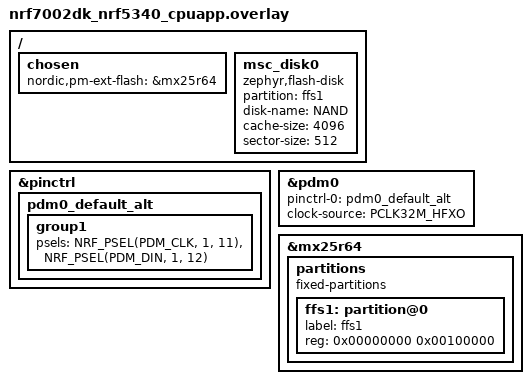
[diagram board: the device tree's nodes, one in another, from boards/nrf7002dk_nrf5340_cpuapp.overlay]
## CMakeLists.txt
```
# SPDX-License-Identifier: Apache-2.0

cmake_minimum_required(VERSION 3.20.0)

find_package(Zephyr REQUIRED HINTS $ENV{ZEPHYR_BASE})
project(reminderGenerativeAI)

target_sources(app PRIVATE 
    src/main.c 
    src/button.c 
    src/reminder.c 
    src/recorder.c 
    src/persistence/persistence.c
)


target_sources_ifdef(CONFIG_WIFI
         app PRIVATE
         src/net/wifi/wifi.c
         src/ai/socket_common.c
         src/ai/whisper.c
         src/ai/completions.c
         )

set(gen_dir ${ZEPHYR_BINARY_DIR}/include/generated/)

generate_inc_file_for_target(
    app
    src/ai/Baltimore\ CyberTrust\ Root.cer
    ${gen_dir}/https-cert.der.inc
    )
```

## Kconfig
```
# Config options for logger sample app

# Copyright (c) 2018 Nordic Semiconductor ASA
# SPDX-License-Identifier: Apache-2.0

mainmenu "Home control with open.ai"

menu "Application configuration"

rsource "Kconfig.net"

config OPENAI_API_KEY
	string "API Key for Open.ai"
	help
	  Specify the API Key for Open.ai


module = MAIN
module-str = Home control by voice
source "subsys/logging/Kconfig.template.log_config"

endmenu

source "Kconfig.zephyr"
```

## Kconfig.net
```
#
# Copyright (c) 2022 Nordic Semiconductor
#
# SPDX-License-Identifier: LicenseRef-Nordic-5-Clause
#

if WIFI

config STA_SAMPLE_SSID
	string "SSID"
	help
	  Specify the SSID to connect

choice  STA_KEY_MGMT_SELECT
	prompt "Security Option"
	default STA_KEY_MGMT_WPA3

config STA_KEY_MGMT_NONE
	bool "Open Security"
	help
	  Enable for Open Security

config STA_KEY_MGMT_WPA2
	bool "WPA2 Security"
	help
	  Enable for WPA2 Security

config STA_KEY_MGMT_WPA2_256
	bool "WPA2 SHA 256 Security"
	help
	  Enable for WPA2-PSK-256 Security

config STA_KEY_MGMT_WPA3
	bool "WPA3 Security"
	help
	  Enable for WPA3 Security
endchoice

config STA_SAMPLE_PASSWORD
	string "Passphrase (WPA2) or password (WPA3)"
	help
	  Specify the Password to connect

endif
```

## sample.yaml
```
sample:
  description: open.ai
  name: open.ai
tests:
  open_ai.debug:
    build_only: true
    integration_platforms:
      - nrf7002dk_nrf5340_cpuapp
    platform_allow: nrf7002dk_nrf5340_cpuapp
```

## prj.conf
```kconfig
#################
# Debugging
#################
# Debug information
CONFIG_DEBUG=y
CONFIG_DEBUG_INFO=y
CONFIG_EXCEPTION_STACK_TRACE=y
CONFIG_THREAD_NAME=y
CONFIG_MPU_STACK_GUARD=y
CONFIG_RESET_ON_FATAL_ERROR=n

CONFIG_INIT_STACKS=y
CONFIG_STACK_SENTINEL=y
#CONFIG_DEBUG_COREDUMP=y
#CONFIG_DEBUG_COREDUMP_BACKEND_LOGGING=y
#CONFIG_STACK_USAGE=y
#CONFIG_THREAD_ANALYZER=y
#CONFIG_THREAD_ANALYZER_USE_LOG=y
#CONFIG_THREAD_ANALYZER_AUTO=y
#CONFIG_SYS_HEAP_RUNTIME_STATS=y



############
# Memory settings
############
CONFIG_SYSTEM_WORKQUEUE_STACK_SIZE=8192
CONFIG_NET_TX_STACK_SIZE=4096

# https://developer.nordicsemi.com/nRF_Connect_SDK/doc/latest/nrf/device_guides/working_with_nrf/nrf70/developing/constrained.html
# Buffers for network and nRF7002
CONFIG_NET_PKT_RX_COUNT=8
CONFIG_NET_PKT_TX_COUNT=8
CONFIG_NET_BUF_RX_COUNT=16
CONFIG_NET_BUF_TX_COUNT=32

CONFIG_NET_BUF_DATA_SIZE=128
CONFIG_HEAP_MEM_POOL_SIZE=51200
CONFIG_HW_STACK_PROTECTION=y
CONFIG_NET_TC_TX_COUNT=1

CONFIG_NRF700X_RX_NUM_BUFS=12
CONFIG_NRF700X_MAX_TX_AGGREGATION=12
CONFIG_NRF700X_MAX_TX_TOKENS=10
CONFIG_NRF700X_TX_MAX_DATA_SIZE=1600
CONFIG_NRF700X_RX_MAX_DATA_SIZE=800
CONFIG_NET_SOCKETPAIR_BUFFER_SIZE=4096



##########
# logging
##########
CONFIG_LOG=y
CONFIG_LOG_MODE_MINIMAL=n
CONFIG_LOG_MODE_DEFERRED=y
CONFIG_LOG_MODE_IMMEDIATE=n
CONFIG_LOG_BUFFER_SIZE=8192
CONFIG_LOG_BACKEND_SHOW_COLOR=n
CONFIG_LOG_BACKEND_UART=y
CONFIG_SHELL_LOG_BACKEND=n

CONFIG_MAIN_LOG_LEVEL_DBG=y
CONFIG_DATE_TIME_LOG_LEVEL_DBG=y
CONFIG_USB_DRIVER_LOG_LEVEL_ERR=y
CONFIG_USB_DEVICE_LOG_LEVEL_ERR=y
CONFIG_USB_MASS_STORAGE_LOG_LEVEL_ERR=y
CONFIG_USB_CDC_ACM_LOG_LEVEL_OFF=y
CONFIG_NET_HTTP_LOG_LEVEL_DBG=y



############
# USB
############
CONFIG_USB_DEVICE_STACK=y
CONFIG_USB_DEVICE_PRODUCT="Feather Chat"
CONFIG_USB_CDC_ACM=n
CONFIG_UART_LINE_CTRL=y
CONFIG_USB_REQUEST_BUFFER_SIZE=2048

CONFIG_USB_DEVICE_VID=0x1234
CONFIG_USB_DEVICE_PID=0x5678

CONFIG_USB_DEVICE_MANUFACTURER="J"
CONFIG_USB_DEVICE_SN="MLB_000000000000"

CONFIG_USB_DEVICE_INITIALIZE_AT_BOOT=n

CONFIG_USB_COMPOSITE_DEVICE=n
CONFIG_USB_MAX_NUM_TRANSFERS=8



############
# Wifi
############
CONFIG_WIFI=y
CONFIG_WIFI_NRF700X=y

# WPA supplicant
CONFIG_WPA_SUPP=y




############
# Networking
############
CONFIG_NETWORKING=y
CONFIG_NET_SOCKETS=y
CONFIG_NET_LOG=y
CONFIG_NET_IPV4=y
CONFIG_NET_UDP=y
CONFIG_NET_TCP=y
CONFIG_NET_DHCPV4=y

CONFIG_NET_L2_ETHERNET=y
CONFIG_NET_CONFIG_SETTINGS=y
CONFIG_NET_SOCKETS_POLL_MAX=6
CONFIG_NET_IF_UNICAST_IPV4_ADDR_COUNT=1
CONFIG_NET_MAX_CONTEXTS=5
CONFIG_NET_CONTEXT_SYNC_RECV=y

CONFIG_NET_MGMT=y
CONFIG_NET_MGMT_EVENT=y
CONFIG_NET_MGMT_EVENT_QUEUE_TIMEOUT=5000
CONFIG_NET_MGMT_EVENT_QUEUE_SIZE=150

CONFIG_NET_SOCKETS_SOCKOPT_TLS=y
CONFIG_NET_SOCKETS_TLS_MAX_CONTEXTS=2
CONFIG_NET_SOCKETS_TLS_SET_MAX_FRAGMENT_LENGTH=y

CONFIG_DNS_RESOLVER=y
CONFIG_DNS_RESOLVER_MAX_SERVERS=1
CONFIG_DNS_SERVER_IP_ADDRESSES=y
CONFIG_DNS_NUM_CONCUR_QUERIES=1
CONFIG_DNS_SERVER1="8.8.8.8"



############
# MbedTLS and security
############
CONFIG_MBEDTLS=y
CONFIG_MBEDTLS_TLS_LIBRARY=y
CONFIG_MBEDTLS_X509_LIBRARY=y
CONFIG_MBEDTLS_PKCS1_V15=y
CONFIG_MBEDTLS_RSA_C=y
CONFIG_MBEDTLS_SSL_SERVER_NAME_INDICATION=y

# These sizes are required to establish ssl connection with open.ai
CONFIG_MBEDTLS_ENABLE_HEAP=y
CONFIG_MBEDTLS_SSL_IN_CONTENT_LEN=4096
CONFIG_MBEDTLS_SSL_OUT_CONTENT_LEN=4096
CONFIG_MBEDTLS_HEAP_SIZE=32768

CONFIG_NRF_SECURITY_ADVANCED=y
CONFIG_NORDIC_SECURITY_BACKEND=y
CONFIG_PSA_WANT_ALG_SHA_1=y
CONFIG_PSA_WANT_ALG_RSA_PKCS1V15_CRYPT=y
CONFIG_PSA_WANT_ALG_RSA_PKCS1V15_SIGN=y

CONFIG_PSA_CRYPTO_DRIVER_CC3XX=n



############
# Other
############
CONFIG_ENTROPY_GENERATOR=y
CONFIG_POSIX_CLOCK=y
CONFIG_POLL=y
CONFIG_PM=y



############
# App
############
CONFIG_HTTP_CLIENT=y

CONFIG_NRFX_PDM=y

CONFIG_DK_LIBRARY=y

CONFIG_CJSON_LIB=y

CONFIG_NEWLIB_LIBC=y
CONFIG_NEWLIB_LIBC_FLOAT_PRINTF=y

CONFIG_DATE_TIME=y
CONFIG_DATE_TIME_NTP=y

CONFIG_AUDIO=y
CONFIG_AUDIO_DMIC=y



############
# Flash / Disk / USB Mass Storage
############
CONFIG_DISK_ACCESS=y
CONFIG_FILE_SYSTEM=y
CONFIG_FAT_FILESYSTEM_ELM=y
CONFIG_FS_FATFS_LFN=y

CONFIG_POSIX_MAX_FDS=16

# Need this when storage is on flash
CONFIG_MPU_ALLOW_FLASH_WRITE=y

CONFIG_FLASH=y
CONFIG_FLASH_MAP=y
CONFIG_FLASH_PAGE_LAYOUT=y
# nRF7002dk does not connect to QSPI
CONFIG_SPI_NOR_FLASH_LAYOUT_PAGE_SIZE=4096

CONFIG_USB_MASS_STORAGE=y
CONFIG_MASS_STORAGE_STACK_SIZE=1024

CONFIG_DISK_DRIVER_FLASH=y
# defaults if CONFIG_DISK_DRIVER_FLASH=y
CONFIG_MASS_STORAGE_DISK_NAME="NAND"
CONFIG_FLASHDISK_VERIFY_PAGE_LAYOUT=y
```

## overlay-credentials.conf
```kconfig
CONFIG_OPENAI_API_KEY="__REPLACE_ME__"

# Security
CONFIG_STA_KEY_MGMT_WPA3=y
CONFIG_STA_SAMPLE_SSID="__REPLACE_ME__"
CONFIG_STA_SAMPLE_PASSWORD="__REPLACE_ME__"
```

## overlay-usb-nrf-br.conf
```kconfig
############
# USB
############
CONFIG_USB_DEVICE_STACK=y
CONFIG_USB_DEVICE_PRODUCT="Feather Chat"
CONFIG_USB_CDC_ACM=y
CONFIG_UART_LINE_CTRL=y
CONFIG_USB_REQUEST_BUFFER_SIZE=2048

CONFIG_USB_DEVICE_VID=0x1234
CONFIG_USB_DEVICE_PID=0x5678

CONFIG_USB_DEVICE_MANUFACTURER="J"
CONFIG_USB_DEVICE_SN="MLB_000000000000"

CONFIG_USB_DEVICE_INITIALIZE_AT_BOOT=n

CONFIG_USB_COMPOSITE_DEVICE=n
CONFIG_USB_MAX_NUM_TRANSFERS=8

#CONFIG_ISR_STACK_SIZE=4096

CONFIG_USB_CDC_ACM_LOG_LEVEL_OFF=y

CONFIG_USB_MASS_STORAGE=y
CONFIG_MASS_STORAGE_STACK_SIZE=1024
CONFIG_USB_DRIVER_LOG_LEVEL_ERR=y
CONFIG_USB_DEVICE_LOG_LEVEL_ERR=y
CONFIG_USB_MASS_STORAGE_LOG_LEVEL_ERR=y

CONFIG_DISK_DRIVER_FLASH=y
# defaults if CONFIG_DISK_DRIVER_FLASH=y
CONFIG_MASS_STORAGE_DISK_NAME="NAND"
CONFIG_FLASHDISK_VERIFY_PAGE_LAYOUT=y
```

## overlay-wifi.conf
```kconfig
############
# Wifi
############
CONFIG_WIFI=y
CONFIG_WIFI_NRF700X=y

# WPA supplicant
CONFIG_WPA_SUPP=y

# Security
CONFIG_STA_KEY_MGMT_WPA3=y
CONFIG_STA_SAMPLE_SSID="__REPLACE_ME__"
CONFIG_STA_SAMPLE_PASSWORD="__REPLACE_ME__"



############
# Networking
############
CONFIG_NETWORKING=y
CONFIG_NET_SOCKETS=y
CONFIG_NET_LOG=y
CONFIG_NET_IPV4=y
CONFIG_NET_UDP=y
CONFIG_NET_TCP=y
CONFIG_NET_DHCPV4=y

CONFIG_NET_L2_ETHERNET=y
CONFIG_NET_CONFIG_SETTINGS=y
CONFIG_NET_SOCKETS_POLL_MAX=6
CONFIG_NET_IF_UNICAST_IPV4_ADDR_COUNT=1
CONFIG_NET_MAX_CONTEXTS=5
CONFIG_NET_CONTEXT_SYNC_RECV=y

CONFIG_NET_MGMT=y
CONFIG_NET_MGMT_EVENT=y
CONFIG_NET_MGMT_EVENT_QUEUE_TIMEOUT=5000
CONFIG_NET_MGMT_EVENT_QUEUE_SIZE=150

CONFIG_NET_SOCKETS_SOCKOPT_TLS=y
CONFIG_NET_SOCKETS_TLS_MAX_CONTEXTS=2
CONFIG_NET_SOCKETS_TLS_SET_MAX_FRAGMENT_LENGTH=y

CONFIG_DNS_RESOLVER=y
CONFIG_DNS_RESOLVER_MAX_SERVERS=1
CONFIG_DNS_SERVER_IP_ADDRESSES=y
CONFIG_DNS_NUM_CONCUR_QUERIES=1
CONFIG_DNS_SERVER1="8.8.8.8"



############
# MbedTLS and security
############
CONFIG_MBEDTLS=y
CONFIG_MBEDTLS_TLS_LIBRARY=y
CONFIG_MBEDTLS_X509_LIBRARY=y
CONFIG_MBEDTLS_PKCS1_V15=y
CONFIG_MBEDTLS_RSA_C=y
CONFIG_MBEDTLS_SSL_SERVER_NAME_INDICATION=y

# These sizes are required to establish ssl connection with open.ai
CONFIG_MBEDTLS_ENABLE_HEAP=y
CONFIG_MBEDTLS_SSL_IN_CONTENT_LEN=4096
CONFIG_MBEDTLS_SSL_OUT_CONTENT_LEN=4096
CONFIG_MBEDTLS_HEAP_SIZE=32768

CONFIG_NRF_SECURITY_ADVANCED=y
CONFIG_NORDIC_SECURITY_BACKEND=y
CONFIG_PSA_WANT_ALG_SHA_1=y
CONFIG_PSA_WANT_ALG_RSA_PKCS1V15_CRYPT=y
CONFIG_PSA_WANT_ALG_RSA_PKCS1V15_SIGN=y

CONFIG_PSA_CRYPTO_DRIVER_CC3XX=n



############
# Memory
############
CONFIG_SYSTEM_WORKQUEUE_STACK_SIZE=8192

# https://developer.nordicsemi.com/nRF_Connect_SDK/doc/latest/nrf/device_guides/working_with_nrf/nrf70/developing/constrained.html
# Buffers for network and nRF7002
CONFIG_NET_PKT_RX_COUNT=8
CONFIG_NET_PKT_TX_COUNT=8
CONFIG_NET_BUF_RX_COUNT=16
CONFIG_NET_BUF_TX_COUNT=32

CONFIG_NET_BUF_DATA_SIZE=128
CONFIG_HEAP_MEM_POOL_SIZE=51200
CONFIG_HW_STACK_PROTECTION=y
CONFIG_NET_TC_TX_COUNT=1

CONFIG_NRF700X_RX_NUM_BUFS=12
CONFIG_NRF700X_MAX_TX_AGGREGATION=12
CONFIG_NRF700X_MAX_TX_TOKENS=10
CONFIG_NRF700X_TX_MAX_DATA_SIZE=1600
CONFIG_NRF700X_RX_MAX_DATA_SIZE=800
CONFIG_NET_SOCKETPAIR_BUFFER_SIZE=4096



############
# Debugging
############
CONFIG_INIT_STACKS=y
CONFIG_STACK_SENTINEL=y
CONFIG_DEBUG_COREDUMP=y
CONFIG_DEBUG_COREDUMP_BACKEND_LOGGING=y
#CONFIG_STACK_USAGE=y
#CONFIG_THREAD_ANALYZER=y
#CONFIG_THREAD_ANALYZER_USE_LOG=y
#CONFIG_THREAD_ANALYZER_AUTO=y
#CONFIG_SYS_HEAP_RUNTIME_STATS=y



############
# Other
############
CONFIG_ENTROPY_GENERATOR=y
CONFIG_POSIX_CLOCK=y
CONFIG_PM=y



############
# App
############
CONFIG_HTTP_CLIENT=y
CONFIG_NET_HTTP_LOG_LEVEL_DBG=y
```

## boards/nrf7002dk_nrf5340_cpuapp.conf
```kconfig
# Need this when storage is on flash
CONFIG_MPU_ALLOW_FLASH_WRITE=y

CONFIG_SPI_NOR_FLASH_LAYOUT_PAGE_SIZE=4096

CONFIG_FLASH=y
CONFIG_FLASH_MAP=y
CONFIG_FLASH_PAGE_LAYOUT=y
```

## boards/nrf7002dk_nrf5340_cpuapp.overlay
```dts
/ {
	chosen {
		nordic,pm-ext-flash = &mx25r64;
	};

	msc_disk0 {
		compatible = "zephyr,flash-disk";
		partition = <&ffs1>;
		// disk-name must be one of "RAM","NAND","CF","SD","SD2","USB","USB2","USB3"
		disk-name = "NAND";
		cache-size = <4096>;
		// when changing sector-size, adapt CONFIG_FS_FATFS_MAX_SS or crash
		sector-size = <512>;
	};
};

&pinctrl {
	pdm0_default_alt: pdm0_default_alt {
		group1 {
			psels = <NRF_PSEL(PDM_CLK, 1, 11)>,
				<NRF_PSEL(PDM_DIN, 1, 12)>;
		};
	};
};

dmic_dev: &pdm0 {
	status = "okay";
	pinctrl-0 = <&pdm0_default_alt>;
	pinctrl-names = "default";
	clock-source = "PCLK32M_HFXO";
};

&mx25r64 {
	partitions {
		compatible = "fixed-partitions";
		#address-cells = <1>;
		#size-cells = <1>;

		ffs1: partition@0 {
			label = "ffs1";			
			reg = <0x00000000 0x00100000>;
		};
	};
};
```

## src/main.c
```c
#include <zephyr/kernel.h>
#include <zephyr/logging/log.h>
#include <zephyr/usb/usb_device.h>

#include "ai/completions.h"
#include "ai/definitions.h"
#include "ai/whisper.h"
#include "button.h"
#include "cJSON.h"
#include "persistence/persistence.h"
#include "recorder.h"
#include "reminder.h"
LOG_MODULE_REGISTER(app, CONFIG_MAIN_LOG_LEVEL);

// Magic global variable that holds the results of the requests to open.ai
extern char response_buf[MAX_EXPECTED_RESPONSE_BODY];

static void parse_json(const char *data) {
  LOG_INF("Parsing completion result %s", data);

  cJSON *jsonRoot = cJSON_Parse(data);
  if (!cJSON_IsObject(jsonRoot)) {
    const char *error_ptr = cJSON_GetErrorPtr();
    if (error_ptr != NULL) {
      LOG_ERR("Error before: %s", error_ptr);
    }
    goto end;
  }

  cJSON *jsonRequest = cJSON_GetObjectItemCaseSensitive(jsonRoot, "request");
  if (!cJSON_IsString(jsonRequest)) {
    LOG_ERR("No request available");
    goto end;
  }
  const char *requestString = jsonRequest->valuestring;

  cJSON *jsonParameter = cJSON_GetObjectItemCaseSensitive(jsonRoot, "parameter");
  if (!cJSON_IsObject(jsonParameter)) {
    LOG_ERR("No parameter available");
    goto end;
  }

  cJSON *jsonName = cJSON_GetObjectItemCaseSensitive(jsonParameter, "name");
  if (!cJSON_IsString(jsonName)) {
    LOG_ERR("No name available");
    goto end;
  }
  const char *nameString = jsonName->valuestring;

  if (strcmp(requestString, "delete") == 0) {
    deleteReminder(nameString);
  } else if (strcmp(requestString, "add") == 0) {
    cJSON *jsonDue = cJSON_GetObjectItemCaseSensitive(jsonParameter, "due");
    if (!cJSON_IsString(jsonDue)) {
      LOG_ERR("No due available");
      goto end;
    }
    const char *dueString = jsonDue->valuestring;
    addReminder(nameString, dueString);
  }

end:
  cJSON_Delete(jsonRoot);
}

static void onRecordingFinished(struct k_work *work) {
  struct work_with_data *work_data = CONTAINER_OF(work, struct work_with_data, work);
  request_transcription(work_data->path);
  response_buf[strcspn(response_buf, "\n")] = 0;
  request_chat_completion(response_buf);
  parse_json(response_buf);
  LOG_INF("NEXT ALARM UNTIL %llu",checkdue());
}

int main(void) {
  int ret;

#if defined(CONFIG_USB_DEVICE_STACK)
  usb_enable(NULL);
#endif

  LOG_INF("Start of ChatGPT");

  k_work_init_delayable(&onRecordingFinishedWork.work, onRecordingFinished);

  fs_init(false);
  button_init();

  while (true) {
    LOG_INF("WAIT FOR BUTTON");
    k_poll(recordButtonEvents, ARRAY_SIZE(recordButtonEvents), K_FOREVER);
    if (recordButtonEvents[0].signal->result == BUTTON_PUSHED) {
      k_poll_signal_reset(&recordButtonSignal);
      LOG_INF("START RECORDING");

      ret = do_pdm_transfer();
      if (ret < 0) {
        return 0;
      }

      LOG_INF("STOP RECORDING");
    }
  }

  LOG_INF("Exiting");
  return 0;
}
```

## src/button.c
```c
#include "button.h"

#include <dk_buttons_and_leds.h>
#include <zephyr/kernel.h>
#include <zephyr/logging/log.h>
LOG_MODULE_REGISTER(button, CONFIG_MAIN_LOG_LEVEL);

#define RECORD_BUTTON_MASK DK_BTN1_MSK

struct k_poll_signal recordButtonSignal;
struct k_poll_event recordButtonEvents[1];

void ButtonEventHandler(uint32_t buttonState, uint32_t hasChanged) {
  if (RECORD_BUTTON_MASK & hasChanged) {
    if (RECORD_BUTTON_MASK & buttonState) {
      // pushed
      k_poll_signal_raise(&recordButtonSignal, BUTTON_PUSHED);
    } else {
      // released
      k_poll_signal_raise(&recordButtonSignal, BUTTON_RELEASED);
    }
  }
}

int button_init() {
  /* Initialize buttons */
  int ret = dk_buttons_init(ButtonEventHandler);
  if (ret) {
    LOG_ERR("dk_buttons_init() failed");
    return ret;
  }

  k_poll_signal_init(&recordButtonSignal);
  k_poll_event_init(recordButtonEvents, K_POLL_TYPE_SIGNAL, K_POLL_MODE_NOTIFY_ONLY,
                    &recordButtonSignal);

  return 0;
}
```

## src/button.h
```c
#pragma once

#include <zephyr/kernel.h>

enum buttonEvent { BUTTON_PUSHED, BUTTON_RELEASED };

extern struct k_poll_signal recordButtonSignal;
extern struct k_poll_event recordButtonEvents[1];

int button_init();
```

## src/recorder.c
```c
#include "recorder.h"

#include <nrfx_pdm.h>
#include <stdio.h>
#include <zephyr/kernel.h>
#include <zephyr/logging/log.h>

#include "button.h"
#include "persistence/persistence.h"

LOG_MODULE_REGISTER(audio_recorder, CONFIG_MAIN_LOG_LEVEL);

struct work_with_data onRecordingFinishedWork;

/* Milliseconds to wait for a block to be read. */
#define READ_TIMEOUT 2000

/* Audio sampling config */
#define AUDIO_CHANNEL_NUM           1
#define AUDIO_SAMPLING_FREQUENCY    8000
#define AUDIO_SAMPLES_PER_MS        (AUDIO_SAMPLING_FREQUENCY / 1000)
#define AUDIO_DSP_SAMPLE_LENGTH_MS  1500
#define AUDIO_DSP_SAMPLE_RESOLUTION (sizeof(short))
#define AUDIO_DSP_SAMPLE_BUFFER_SIZE \
  (AUDIO_SAMPLES_PER_MS * AUDIO_DSP_SAMPLE_LENGTH_MS * AUDIO_DSP_SAMPLE_RESOLUTION)
#define PDM_CLK_PIN                 43  // 32+11 = p1.11
#define PDM_DIN_PIN                 44  // 32+12 = p1.12
#define BUFFER_COUNT                4

K_MEM_SLAB_DEFINE_STATIC(mem_slab, AUDIO_DSP_SAMPLE_BUFFER_SIZE, BUFFER_COUNT, sizeof(void *));
K_MSGQ_DEFINE(rx_queue, sizeof(void *), 4, sizeof(void *));


// http://soundfile.sapp.org/doc/WaveFormat/
struct wav_hdr {
  uint8_t RIFF[4];
  uint32_t ChunkSize;
  uint8_t WAVE[4];
  uint8_t fmt[4];
  uint32_t Subchunk1Size;
  uint16_t AudioFormat;
  uint16_t NumOfChan;
  uint32_t SamplesPerSec;
  uint32_t bytesPerSec;
  uint16_t blockAlign;
  uint16_t bitsPerSample;
  uint8_t Subchunk2ID[4];
  uint32_t Subchunk2Size;
};

const struct wav_hdr WAV_DEFAULTS = {{'R', 'I', 'F', 'F'},
                                     0,
                                     {'W', 'A', 'V', 'E'},
                                     {'f', 'm', 't', ' '},
                                     16,
                                     1,
                                     AUDIO_CHANNEL_NUM,
                                     AUDIO_SAMPLING_FREQUENCY,
                                     AUDIO_SAMPLING_FREQUENCY * 2,
                                     2,
                                     8 * sizeof(short),
                                     {'d', 'a', 't', 'a'},
                                     0};


static void samples_callback(nrfx_pdm_evt_t const *p_evt) {
  if (p_evt->error != 0) {
    LOG_ERR("ERR: PDM handler error ocured");
    LOG_ERR("ERR: samples_callback error: %d, %d", p_evt->error, p_evt->buffer_requested);
    return;
  }

  if (p_evt->buffer_requested) {
    void *buffer;
    int err;

    err = k_mem_slab_alloc(&mem_slab, &buffer, K_NO_WAIT);

    if (err < 0) {
      LOG_ERR("Failed to allocate buffer: %d", err);
    } else {
      // size is 16-bit words
      err = nrfx_pdm_buffer_set(buffer, AUDIO_DSP_SAMPLE_BUFFER_SIZE / 2);
      if (err != NRFX_SUCCESS) {
        LOG_ERR("Failed to set buffer: 0x%08x", err);
      }
    }
  }

  if (p_evt->buffer_released != NULL) {
    k_msgq_put(&rx_queue, &p_evt->buffer_released, K_NO_WAIT);
  }
  
  uint32_t used = k_mem_slab_num_used_get(&mem_slab);
  LOG_INF("Allocated %d of %d bytes", used * AUDIO_DSP_SAMPLE_BUFFER_SIZE,
          BUFFER_COUNT * AUDIO_DSP_SAMPLE_BUFFER_SIZE);
}

static bool setup_nrf_pdm(nrfx_pdm_event_handler_t event_handler) {
  nrfx_err_t err;

  // PDM driver configuration
  nrfx_pdm_config_t config_pdm = NRFX_PDM_DEFAULT_CONFIG(PDM_CLK_PIN, PDM_DIN_PIN);
  if (AUDIO_SAMPLING_FREQUENCY == 8000) {
    // taken from firmware-nordic-thingy53/drivers/vm3011/vm3011.c l.346
    config_pdm.clock_freq = 0x04104000UL;
    config_pdm.ratio = NRF_PDM_RATIO_64X;
  } else if (AUDIO_SAMPLING_FREQUENCY == 16000) {
    config_pdm.clock_freq = NRF_PDM_FREQ_1280K;
    config_pdm.ratio = NRF_PDM_RATIO_80X;
  }
  config_pdm.edge = NRF_PDM_EDGE_LEFTRISING;
  config_pdm.gain_l = NRF_PDM_GAIN_MAXIMUM;
  config_pdm.gain_r = NRF_PDM_GAIN_MAXIMUM;
  // defaults below
  config_pdm.mode = NRF_PDM_MODE_MONO;
  config_pdm.mclksrc = PDM_MCLKCONFIG_SRC_PCLK32M;
  config_pdm.interrupt_priority = NRFX_PDM_DEFAULT_CONFIG_IRQ_PRIORITY;

  IRQ_DIRECT_CONNECT(PDM0_IRQn, IRQ_PRIO_LOWEST, nrfx_pdm_irq_handler, 0);

  err = nrfx_pdm_init(&config_pdm, event_handler);
  if (err != NRFX_SUCCESS) {
    LOG_ERR("Failed to init PDM");
    return false;
  } else {
    if (!irq_is_enabled(PDM0_IRQn)) {
      irq_enable(PDM0_IRQn);
    }
    LOG_DBG("PDM init ok");
    return true;
  }
}

int do_pdm_transfer() {
  int ret;

  nrfx_pdm_uninit();
  if (!setup_nrf_pdm(samples_callback)) {
    LOG_ERR("Error microphone init");
    return -1;
  }

  ret = nrfx_pdm_start();
  if (ret != NRFX_SUCCESS) {
    LOG_ERR("Error microphone start");
    return ret;
  }

  // path of temp file
  uint32_t uptime = (uint32_t)(k_uptime_get() / 1000);
  char path[32];
  snprintf(path, 32, "rec-%d", uptime);

  // skip the first frame (1.5s!) since there is a click sound in the first 500ms
  uint8_t skip = 1;
  // total size to update the wave hearder
  uint32_t total_size = 0;
  struct wav_hdr header = WAV_DEFAULTS;
  fs_appendData(path, &header, sizeof(header));

  for (int i = 0; true; ++i) {
    void *buffer;

    ret = k_msgq_get(&rx_queue, &buffer, SYS_TIMEOUT_MS(READ_TIMEOUT));

    if (ret != 0) {
      LOG_ERR("No audio data to be read. Finished");

      ret = nrfx_pdm_stop();
      if (ret != NRFX_SUCCESS) {
        LOG_ERR("ERR: PDM Could not stop PDM sampling, error = %d", ret);
      }      

      break;
    } else {
      LOG_DBG("Released buffer %p", buffer);
    }

    if (skip > 0) {
      skip--;
    } else {
      fs_appendData(path, buffer, AUDIO_DSP_SAMPLE_BUFFER_SIZE);
      total_size += AUDIO_DSP_SAMPLE_BUFFER_SIZE;
    }

    k_mem_slab_free(&mem_slab, buffer);

    // Check if the recording shall be stopped
    int rc = k_poll(recordButtonEvents, ARRAY_SIZE(recordButtonEvents), K_NO_WAIT);
    if (rc == 0 && recordButtonEvents[0].signal->result == BUTTON_RELEASED) {
      k_poll_signal_reset(&recordButtonSignal);

      ret = nrfx_pdm_stop();
      if (ret != NRFX_SUCCESS) {
        LOG_ERR("ERR: PDM Could not stop PDM sampling, error = %d", ret);
      }
    }
  }

  // update the wave header
  header.Subchunk2Size = total_size;
  header.ChunkSize = header.Subchunk2Size + 36;
  fs_overwriteData(path, &header, sizeof(header), 0);

  // schedule the transcription
  memcpy(onRecordingFinishedWork.path, path, sizeof(path));
  k_work_reschedule(&onRecordingFinishedWork.work, K_SECONDS(2));

  return ret;
}
```

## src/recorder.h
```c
#pragma once

#include <zephyr/kernel.h>

// interface between main and recorder
struct work_with_data {
  struct k_work_delayable work;
  char path[32];
};

extern struct work_with_data onRecordingFinishedWork;

int do_pdm_transfer();
```

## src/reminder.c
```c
#include "reminder.h"

#include <date_time.h>
#include <stdio.h>
#include <zephyr/kernel.h>
#include <zephyr/logging/log.h>
LOG_MODULE_REGISTER(reminder, CONFIG_MAIN_LOG_LEVEL);

struct reminder reminders[10];

int64_t parseTime(const char *dueDate) {
  // https://stackoverflow.com/questions/2722606/how-to-parse-a-string-into-a-datetime-struct-in-c
  struct tm *parsedTime;
  int hour, minute, month, day;
  if (sscanf(dueDate, "%d-%d %d:%d", &month, &day, &hour, &minute) != EOF) {
    time_t rawTime = 0;
    parsedTime = localtime(&rawTime);

    // tm_year is years since 1900
    parsedTime->tm_year = 2023 - 1900;
    // tm_months is months since january
    parsedTime->tm_mon = month - 1;
    parsedTime->tm_mday = day;
    parsedTime->tm_hour = hour;
    parsedTime->tm_min = minute;
    return mktime(parsedTime);
  }
  return -1;
}

void addReminder(const char *name, const char *dueDate) {
  for (size_t i = 0; i < ARRAY_SIZE(reminders); i++) {
    if (reminders[i].name[0] == 0) {
      strncpy(reminders[i].name, name, 50);
      reminders[i].dueDate = parseTime(dueDate);
      LOG_INF("Added reminder %s at %llu", reminders[i].name, reminders[i].dueDate);
      break;
    }
  }
}

void deleteReminder(const char *name) {
  for (size_t i = 0; i < ARRAY_SIZE(reminders); i++) {
    if (strcmp(reminders[i].name, name) == 0) {
      LOG_INF("Delete reminder %s at %llu", reminders[i].name, reminders[i].dueDate);
      reminders[i].name[0] = 0;
      break;
    }
  }
}

int64_t checkdue() {
  int64_t timeUntilNextDue = LONG_MAX;
  int64_t now = -1;
  int rc = date_time_now(&now);
  if (rc >= 0) {
    now = now / 1000 + TIME_ZONE_SHIFT;

    for (size_t i = 0; i < ARRAY_SIZE(reminders); i++) {
      if (reminders[i].name[0] != 0) {
        int64_t remainingTime = reminders[i].dueDate - now;
        LOG_INF("Check reminder %s at %llu, remaining %llu", reminders[i].name, reminders[i].dueDate,
                remainingTime);
        timeUntilNextDue = MIN(timeUntilNextDue, remainingTime);
      }
    }
  }
  return timeUntilNextDue;
}
```

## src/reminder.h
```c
#pragma once

#include <zephyr/kernel.h>

#define TIME_ZONE_SHIFT (9 * 60 * 60)

struct reminder {
  char name[50];
  int64_t dueDate;
};

void addReminder(const char *name, const char *dueDate);
void deleteReminder(const char *name);
int64_t checkdue();
```

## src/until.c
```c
#include <zephyr/sys/sys_heap.h>

#if defined(CONFIG_SYS_HEAP_RUNTIME_STATS)
extern struct sys_heap _system_heap;
#endif

void print_sys_memory_stats(void) {
#if defined(CONFIG_SYS_HEAP_RUNTIME_STATS)
  int err;
  struct sys_memory_stats kernel_stats;

  err = sys_heap_runtime_stats_get(&_system_heap, &kernel_stats);
  if (err) {
    LOG_INF("heap: failed to read kernel heap statistics, error: %d", err);
  } else {
    LOG_INF("kernel heap statistics:");
    LOG_INF("free:           %6d", kernel_stats.free_bytes);
    LOG_INF("allocated:      %6d", kernel_stats.allocated_bytes);
    LOG_INF("max. allocated: %6d\n", kernel_stats.max_allocated_bytes);
  }
#endif /* CONFIG_SYS_HEAP_RUNTIME_STATS */
}
```
